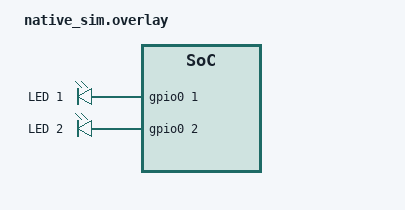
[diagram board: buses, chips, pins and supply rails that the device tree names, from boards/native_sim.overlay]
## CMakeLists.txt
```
# SPDX-License-Identifier: Apache-2.0

cmake_minimum_required(VERSION 3.28.0)

find_package(Zephyr REQUIRED HINTS $ENV{ZEPHYR_BASE})
project(projeto)

target_sources(app PRIVATE src/main.c src/led_ctrl.c)
```

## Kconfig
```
# SPDX-License-Identifier: Apache-2.0

menu "Modulo de LED (led_ctrl)"

config APP_LED_PERIOD_SLOW_MS
	int "Periodo do padrao lento (ms, ciclo completo aceso+apagado)"
	default 2000
	range 2 60000

config APP_LED_PERIOD_NORMAL_MS
	int "Periodo do padrao normal (ms, ciclo completo aceso+apagado)"
	default 1000
	range 2 60000

config APP_LED_PERIOD_FAST_MS
	int "Periodo do padrao rapido (ms, ciclo completo aceso+apagado)"
	default 250
	range 2 60000

config APP_LED_MAX_ALIASES
	int "Quantos aliases ledN do devicetree procurar (led0 .. ledN-1)"
	default 8
	range 1 64
	help
	  O modulo usa todo alias led0, led1, ... que existir abaixo deste
	  limite. LED novo exige apenas um alias novo no devicetree.

endmenu

source "Kconfig.zephyr"
```

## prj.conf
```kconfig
# nothing here
CONFIG_GPIO=y
CONFIG_GPIO_EMUL=y
```

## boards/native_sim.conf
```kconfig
# Liga a UART0 ao stdin/stdout do terminal, para ler o espaço digitado.
CONFIG_SERIAL=y
CONFIG_UART_NATIVE_PTY_0_ON_STDINOUT=y
```

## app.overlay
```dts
#include <zephyr/dt-bindings/input/input-event-codes.h>

/ {
        aliases {
                sw0 = &button0;
        };
        buttons {
                compatible = "gpio-keys";
                btn: button0 {
                        label = "SW0";
                        gpios = <&gpio0 1 GPIO_ACTIVE_HIGH>;
                };
        }
        
}
```

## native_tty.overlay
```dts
/*
 * Troca a uart1 do native_sim para o driver native_tty, que conversa
 * com um TTY real do host. Crie o par de terminais antes de rodar:
 *   socat -d -d pty,raw,echo=0,link=/tmp/ttyV0 pty,raw,echo=0,link=/tmp/ttyV1
 * Build:
 *   west build -p -b native_sim -- -DEXTRA_DTC_OVERLAY_FILE=native_tty.overlay
 */

&uart1 {
	compatible = "zephyr,native-tty-uart";
	current-speed = <115200>;
	serial-port = "/tmp/ttyV0";
	status = "okay";
};
```

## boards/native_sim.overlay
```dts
/* O native_sim já define led0 (gpio0 pino 0); acrescenta led1 e led2. */
/ {
	aliases {
		led1 = &led1;
		led2 = &led2;
	};
};

&leds {
	led1: led_1 {
		gpios = <&gpio0 1 GPIO_ACTIVE_HIGH>;
		label = "LED 1";
	};

	led2: led_2 {
		gpios = <&gpio0 2 GPIO_ACTIVE_HIGH>;
		label = "LED 2";
	};
};
```

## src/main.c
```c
/*******************************************************************
 * @file main.c
 *
 * @brief Main file.
 * @author João Matheus Nascimento Dias (jmnd@ic.ufal.br)
 * @version 0.1
 * @date 19/10/2026
 *******************************************************************/
#include "led_ctrl.h"

#include <zephyr/kernel.h>
#include <zephyr/logging/log.h>

LOG_MODULE_REGISTER(main, LOG_LEVEL_DBG);

/* Padrão de cada LED na demonstração (LED i usa o padrão i % LED_PATTERN_COUNT). */
static const enum led_pattern demo_pattern[LED_PATTERN_COUNT] = {
	LED_PATTERN_SLOW,
	LED_PATTERN_FAST,
	LED_PATTERN_NORMAL,
};

int main(void)
{
	int ret;

	LOG_INF("Atividade 05: LEDs independentes com um k_timer (%s)", CONFIG_BOARD);

	ret = led_ctrl_init();
	if (ret != 0) {
		LOG_ERR("led_ctrl_init falhou: %d", ret);
		return ret;
	}

	for (size_t i = 0; i < led_ctrl_count(); i++) {
		enum led_pattern pattern = demo_pattern[i % LED_PATTERN_COUNT];

		ret = led_ctrl_blink((int)i, pattern);
		if (ret != 0) {
			LOG_ERR("led_ctrl_blink(%zu) falhou: %d", i, ret);
			return ret;
		}
		LOG_INF("LED %zu piscando no padrao %d", i, (int)pattern);
	}

	/* O pisca segue pelo timer; main pode terminar. */
	return 0;
}
```

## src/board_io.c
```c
/*******************************************************************
 * @file board_io.c
 *
 * @brief LED e botão obtidos pelo devicetree (aliases led0 e sw0).
 *******************************************************************/

#include "board_io.h"

#include <zephyr/drivers/gpio.h>
#include <zephyr/kernel.h>

static const struct gpio_dt_spec led = GPIO_DT_SPEC_GET(DT_ALIAS(led0), gpios);
static const struct gpio_dt_spec button = GPIO_DT_SPEC_GET(DT_ALIAS(sw0), gpios);

/* Ler de volta um pino de saída não é portátil: guarda o estado aqui. */
static bool led_state;

int board_io_init(void)
{
	int ret;

	if (!gpio_is_ready_dt(&led) || !gpio_is_ready_dt(&button)) {
		return -ENODEV;
	}

	ret = gpio_pin_configure_dt(&led, GPIO_OUTPUT_INACTIVE);
	if (ret != 0) {
		return ret;
	}

	return gpio_pin_configure_dt(&button, GPIO_INPUT);
}

static int led_set(bool on)
{
	int ret = gpio_pin_set_dt(&led, on ? 1 : 0);

	if (ret == 0) {
		led_state = on;
	}
	return ret;
}

static bool led_get(void)
{
	return led_state;
}

static int button_get(void)
{
	return gpio_pin_get_dt(&button);
}

static int64_t uptime_ms(void)
{
	return k_uptime_get();
}

const struct command_hal board_hal = {
	.led_set = led_set,
	.led_get = led_get,
	.button_get = button_get,
	.uptime_ms = uptime_ms,
};
```

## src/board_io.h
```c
/*******************************************************************
 * @file board_io.h
 *
 * @brief LED e botão obtidos pelo devicetree (aliases led0 e sw0).
 *******************************************************************/

#pragma once

#include "command.h"

/* Configura led0 (saída, apagado) e sw0 (entrada). */
int board_io_init(void);

/* Implementação real das operações usadas pelos comandos. */
extern const struct command_hal board_hal;
```

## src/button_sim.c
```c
/*******************************************************************
 * @file button_sim.c
 *
 * @brief Simula o botão sw0 no native_sim: cada espaço digitado no
 *        terminal (via UART0 em stdin) gera um aperto no pino emulado.
 *******************************************************************/

#include <zephyr/device.h>
#include <zephyr/drivers/gpio.h>
#include <zephyr/drivers/gpio/gpio_emul.h>
#include <zephyr/drivers/uart.h>
#include <zephyr/kernel.h>

#define PRESS_TIME_MS 50
#define POLL_TIME_MS  10

static const struct device *const uart = DEVICE_DT_GET(DT_NODELABEL(uart0));
static const struct gpio_dt_spec button = GPIO_DT_SPEC_GET(DT_ALIAS(sw0), gpios);

static void button_sim_thread(void)
{
	unsigned char c;

	while (true) {
		if (uart_poll_in(uart, &c) == 0 && c == ' ') {
			/* Nível físico: ativo = 1 (GPIO_ACTIVE_HIGH no overlay). */
			gpio_emul_input_set(button.port, button.pin, 1);
			k_msleep(PRESS_TIME_MS);
			gpio_emul_input_set(button.port, button.pin, 0);
		}
		k_msleep(POLL_TIME_MS);
	}
}

K_THREAD_DEFINE(button_sim, 1024, button_sim_thread, NULL, NULL, NULL,
		K_LOWEST_APPLICATION_THREAD_PRIO, 0, 0);
```

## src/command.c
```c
/*******************************************************************
 * @file command.c
 *
 * @brief Implementação do parser/dispatcher de comandos (Atividade-04).
 *
 * Baseado na tabela de function pointers da Atividade-02, agora
 * indexada pelo nome do comando em vez de um enum.
 *******************************************************************/

#include "command.h"

#include <ctype.h>
#include <stdarg.h>
#include <stdio.h>
#include <string.h>
#include <strings.h>

struct command {
	const char *name;
	const char *help;
	command_handler_t handler;
};

static int handle_help(const struct command_hal *hal, const char *arg, struct cmd_out *out);
static int handle_led(const struct command_hal *hal, const char *arg, struct cmd_out *out);
static int handle_btn(const struct command_hal *hal, const char *arg, struct cmd_out *out);
static int handle_uptime(const struct command_hal *hal, const char *arg, struct cmd_out *out);
static int handle_echo(const struct command_hal *hal, const char *arg, struct cmd_out *out);

static const struct command command_table[] = {
	{"HELP", "HELP: lista os comandos", handle_help},
	{"LED", "LED [ON|OFF]: liga/desliga o led0 ou mostra seu estado", handle_led},
	{"BTN", "BTN: le o botao sw0", handle_btn},
	{"UPTIME", "UPTIME: tempo desde o boot em ms", handle_uptime},
	{"ECHO", "ECHO <texto>: devolve o texto", handle_echo},
};

#define COMMAND_TABLE_SIZE (sizeof(command_table) / sizeof(command_table[0]))

/* Acrescenta texto formatado ao buffer, truncando sem estourar. */
static void out_printf(struct cmd_out *out, const char *fmt, ...)
{
	va_list args;
	int n;

	if (out->len >= out->size) {
		return;
	}

	va_start(args, fmt);
	n = vsnprintf(out->buf + out->len, out->size - out->len, fmt, args);
	va_end(args);

	if (n < 0) {
		return;
	}

	out->len += (size_t)n;
	if (out->len >= out->size) {
		out->len = out->size - 1;
	}
}

static bool arg_is_empty(const char *arg)
{
	while (isspace((unsigned char)*arg)) {
		arg++;
	}
	return *arg == '\0';
}

int parse_command(const char *cmd)
{
	if (cmd == NULL) {
		return -1;
	}
	if (strcasecmp(cmd, "ON") == 0) {
		return 1;
	}
	if (strcasecmp(cmd, "OFF") == 0) {
		return 0;
	}
	return -1;
}

static int handle_help(const struct command_hal *hal, const char *arg, struct cmd_out *out)
{
	(void)hal;

	if (!arg_is_empty(arg)) {
		return -ENOCMD;
	}

	for (size_t i = 0; i < COMMAND_TABLE_SIZE; i++) {
		out_printf(out, "%s\r\n", command_table[i].help);
	}
	return 0;
}

static int handle_led(const struct command_hal *hal, const char *arg, struct cmd_out *out)
{
	char word[8];
	size_t len;
	int on;

	if (arg_is_empty(arg)) {
		out_printf(out, "LED: %s\r\n", hal->led_get() ? "ON" : "OFF");
		return 0;
	}

	/* Isola o argumento sem espaços nas pontas para o parse_command. */
	while (isspace((unsigned char)*arg)) {
		arg++;
	}
	len = strlen(arg);
	while (len > 0 && isspace((unsigned char)arg[len - 1])) {
		len--;
	}
	if (len >= sizeof(word)) {
		return -ENOCMD;
	}
	memcpy(word, arg, len);
	word[len] = '\0';

	on = parse_command(word);
	if (on < 0) {
		return -ENOCMD;
	}

	if (hal->led_set(on == 1) != 0) {
		out_printf(out, "ERR: led failure\r\n");
		return 0;
	}
	out_printf(out, "OK\r\n");
	return 0;
}

static int handle_btn(const struct command_hal *hal, const char *arg, struct cmd_out *out)
{
	int value;

	if (!arg_is_empty(arg)) {
		return -ENOCMD;
	}

	value = hal->button_get();
	if (value < 0) {
		out_printf(out, "ERR: button failure\r\n");
		return 0;
	}
	out_printf(out, "BTN: %d\r\n", value ? 1 : 0);
	return 0;
}

static int handle_uptime(const struct command_hal *hal, const char *arg, struct cmd_out *out)
{
	if (!arg_is_empty(arg)) {
		return -ENOCMD;
	}

	out_printf(out, "UPTIME: %lld ms\r\n", (long long)hal->uptime_ms());
	return 0;
}

static int handle_echo(const struct command_hal *hal, const char *arg, struct cmd_out *out)
{
	(void)hal;

	out_printf(out, "%s\r\n", arg);
	return 0;
}

uint16_t dispatch(const struct command_hal *hal, const char *line, char *out, size_t out_size)
{
	struct cmd_out o = {.buf = out, .size = out_size, .len = 0};
	const char *arg;
	size_t name_len;

	if (out_size == 0) {
		return ENOCMD;
	}
	out[0] = '\0';

	while (*line == ' ') {
		line++;
	}
	if (*line == '\0') {
		return 0;
	}

	/* Nome = primeira palavra; argumento = tudo após o primeiro espaço. */
	arg = strchr(line, ' ');
	if (arg != NULL) {
		name_len = (size_t)(arg - line);
		arg++;
	} else {
		name_len = strlen(line);
		arg = "";
	}

	for (size_t i = 0; i < COMMAND_TABLE_SIZE; i++) {
		const struct command *cmd = &command_table[i];

		if (strlen(cmd->name) == name_len && strncasecmp(cmd->name, line, name_len) == 0) {
			if (cmd->handler(hal, arg, &o) == 0) {
				return 0;
			}
			break;
		}
	}

	o.len = 0;
	out[0] = '\0';
	out_printf(&o, "ERR: unknown command\r\n");
	return ENOCMD;
}
```

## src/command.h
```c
/*******************************************************************
 * @file command.h
 *
 * @brief Parser e dispatcher de comandos em texto (Atividade-04).
 *
 * Camada pura: não chama UART, GPIO nem printk. Recebe uma linha,
 * consulta a tabela de comandos (function pointers) e escreve a
 * resposta num buffer. O acesso ao hardware é injetado via
 * struct command_hal, o que permite testar com fakes.
 *******************************************************************/

#pragma once

#include <stdbool.h>
#include <stddef.h>
#include <stdint.h>

#define ENOCMD 1 /* Codigo de erro comando não existe */

/* Operações de hardware usadas pelos comandos. */
struct command_hal {
	int (*led_set)(bool on);
	bool (*led_get)(void);
	int (*button_get)(void);
	int64_t (*uptime_ms)(void);
};

/* Cursor de escrita no buffer de resposta. */
struct cmd_out {
	char *buf;
	size_t size;
	size_t len;
};

/* Retorna 0 em sucesso ou -ENOCMD se o argumento não for aceito. */
typedef int (*command_handler_t)(const struct command_hal *hal, const char *arg,
				 struct cmd_out *out);

/* "ON" -> 1, "OFF" -> 0 (sem diferenciar maiúsculas), qualquer outro -> -1. */
int parse_command(const char *cmd);

/*
 * Executa a linha e escreve a resposta em out (cada linha terminada em
 * "\r\n", string sempre terminada em NUL). Linha vazia gera resposta vazia.
 * Retorna 0 ou ENOCMD (resposta "ERR: unknown command").
 */
uint16_t dispatch(const struct command_hal *hal, const char *line, char *out, size_t out_size);
```

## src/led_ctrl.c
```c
/*******************************************************************
 * @file led_ctrl.c
 *
 * @brief LEDs independentes multiplexados em um único k_timer.
 *
 * Cada LED guarda o seu próximo instante de troca (deadline absoluto,
 * em ticks). O timer é one-shot e sempre rearmado para o menor deadline;
 * como os deadlines são absolutos, rearmar por causa de um LED não muda
 * a fase nem o período dos outros. LED parado tem deadline LED_NEVER,
 * então callback e reagendamento só comparam deadlines.
 *******************************************************************/

#include "led_ctrl.h"

#include <errno.h>
#include <stdint.h>

#include <zephyr/drivers/gpio.h>
#include <zephyr/kernel.h>
#include <zephyr/logging/log.h>
#include <zephyr/spinlock.h>
#include <zephyr/sys/util.h>

LOG_MODULE_REGISTER(led_ctrl, LOG_LEVEL_INF);

#define LED_NEVER INT64_MAX

/* Uma entrada por alias ledN existente no devicetree. */
#define LED_SPEC(i, _)                                                                             \
	IF_ENABLED(DT_HAS_ALIAS(led##i), (GPIO_DT_SPEC_GET(DT_ALIAS(led##i), gpios), ))

static const struct gpio_dt_spec led_specs[] = {LISTIFY(CONFIG_APP_LED_MAX_ALIASES, LED_SPEC, ())};

#define LED_COUNT ARRAY_SIZE(led_specs)

BUILD_ASSERT(LED_COUNT > 0, "defina ao menos o alias led0 no devicetree");

/* Período (ciclo completo, ms) de cada padrão, indexado por enum led_pattern. */
static const uint32_t pattern_period_ms[LED_PATTERN_COUNT] = {
	[LED_PATTERN_SLOW] = CONFIG_APP_LED_PERIOD_SLOW_MS,
	[LED_PATTERN_NORMAL] = CONFIG_APP_LED_PERIOD_NORMAL_MS,
	[LED_PATTERN_FAST] = CONFIG_APP_LED_PERIOD_FAST_MS,
};

struct led_state {
	enum led_pattern pattern;
	k_ticks_t half_period; /* intervalo entre trocas de nível */
	k_ticks_t deadline;    /* próxima troca (uptime em ticks) ou LED_NEVER */
	bool blinking;
};

static struct led_state leds[LED_COUNT];
static struct k_timer led_timer;
static bool timer_initialized;
static struct k_spinlock lock;

/* Ação aplicada a um LED com o lock tomado. */
typedef int (*led_action_fn)(size_t idx, enum led_pattern pattern);

/* Arma o timer para o deadline mais próximo. Chamar com o lock tomado. */
static void reschedule(void)
{
	k_ticks_t next = LED_NEVER;

	for (size_t i = 0; i < LED_COUNT; i++) {
		next = MIN(next, leds[i].deadline);
	}

	if (next == LED_NEVER) {
		k_timer_stop(&led_timer);
		return;
	}
	k_timer_start(&led_timer, K_TIMEOUT_ABS_TICKS(next), K_NO_WAIT);
}

/* Contexto de ISR: só GPIO, deadlines e rearme. */
static void led_timer_expiry(struct k_timer *timer)
{
	k_spinlock_key_t key = k_spin_lock(&lock);
	k_ticks_t now = k_uptime_ticks();

	ARG_UNUSED(timer);

	for (size_t i = 0; i < LED_COUNT; i++) {
		if (leds[i].deadline <= now) {
			(void)gpio_pin_toggle_dt(&led_specs[i]);
			leds[i].deadline += leds[i].half_period;
		}
	}
	reschedule();

	k_spin_unlock(&lock, key);
}

static void stop_blink(size_t idx)
{
	leds[idx].blinking = false;
	leds[idx].deadline = LED_NEVER;
}

static int action_on(size_t idx, enum led_pattern pattern)
{
	ARG_UNUSED(pattern);
	stop_blink(idx);
	return gpio_pin_set_dt(&led_specs[idx], 1);
}

static int action_off(size_t idx, enum led_pattern pattern)
{
	ARG_UNUSED(pattern);
	stop_blink(idx);
	return gpio_pin_set_dt(&led_specs[idx], 0);
}

static int action_toggle(size_t idx, enum led_pattern pattern)
{
	ARG_UNUSED(pattern);
	stop_blink(idx);
	return gpio_pin_toggle_dt(&led_specs[idx]);
}

static int action_blink(size_t idx, enum led_pattern pattern)
{
	struct led_state *led = &leds[idx];
	int ret = gpio_pin_set_dt(&led_specs[idx], 1);

	if (ret != 0) {
		stop_blink(idx);
		return ret;
	}

	led->pattern = pattern;
	led->half_period = k_ms_to_ticks_ceil64(pattern_period_ms[pattern] / 2U);
	led->deadline = k_uptime_ticks() + led->half_period;
	led->blinking = true;
	return 0;
}

/* Único lugar que trata "um LED ou todos": resolve o intervalo e aplica a ação. */
static int led_apply(int led, led_action_fn action, enum led_pattern pattern)
{
	size_t first = 0;
	size_t last = LED_COUNT;
	k_spinlock_key_t key;
	int ret = 0;

	if (led != LED_CTRL_ALL) {
		if (led < 0 || (size_t)led >= LED_COUNT) {
			LOG_ERR("LED invalido: %d (existem %zu)", led, LED_COUNT);
			return -EINVAL;
		}
		first = (size_t)led;
		last = first + 1;
	}

	if (!timer_initialized) {
		LOG_ERR("led_ctrl_init() ainda nao foi chamada");
		return -EPERM;
	}

	key = k_spin_lock(&lock);
	for (size_t i = first; i < last && ret == 0; i++) {
		ret = action(i, pattern);
	}
	reschedule();
	k_spin_unlock(&lock, key);

	return ret;
}

int led_ctrl_init(void)
{
	k_spinlock_key_t key;

	for (size_t i = 0; i < LED_COUNT; i++) {
		if (!gpio_is_ready_dt(&led_specs[i])) {
			LOG_ERR("controlador do LED %zu (%s) nao esta pronto", i,
				led_specs[i].port->name);
			return -ENODEV;
		}
	}

	/* k_timer_init num timer ativo corromperia a fila de timeouts: só na 1a vez. */
	if (!timer_initialized) {
		k_timer_init(&led_timer, led_timer_expiry, NULL);
		timer_initialized = true;
	}

	key = k_spin_lock(&lock);
	k_timer_stop(&led_timer);
	for (size_t i = 0; i < LED_COUNT; i++) {
		stop_blink(i);
	}
	k_spin_unlock(&lock, key);

	for (size_t i = 0; i < LED_COUNT; i++) {
		int ret = gpio_pin_configure_dt(&led_specs[i], GPIO_OUTPUT_INACTIVE);

		if (ret != 0) {
			LOG_ERR("falha ao configurar LED %zu: %d", i, ret);
			return ret;
		}
	}

	return 0;
}

size_t led_ctrl_count(void)
{
	return LED_COUNT;
}

int led_ctrl_on(int led)
{
	return led_apply(led, action_on, LED_PATTERN_SLOW);
}

int led_ctrl_off(int led)
{
	return led_apply(led, action_off, LED_PATTERN_SLOW);
}

int led_ctrl_toggle(int led)
{
	return led_apply(led, action_toggle, LED_PATTERN_SLOW);
}

int led_ctrl_blink(int led, enum led_pattern pattern)
{
	if ((unsigned int)pattern >= LED_PATTERN_COUNT) {
		LOG_ERR("padrao invalido: %d", (int)pattern);
		return -EINVAL;
	}
	return led_apply(led, action_blink, pattern);
}
```

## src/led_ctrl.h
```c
/*******************************************************************
 * @file led_ctrl.h
 *
 * @brief Driver de LEDs independentes multiplexados em um único k_timer.
 *
 * O resto do código pede "LED 1 piscando devagar" e não sabe nada de
 * timer. Os LEDs vêm do devicetree (aliases led0, led1, ...); o índice
 * de cada LED é a sua posição nessa lista.
 *
 * Toda função de ação aceita LED_CTRL_ALL para agir em todos os LEDs.
 * LED ou padrão fora do intervalo retorna -EINVAL.
 *******************************************************************/

#pragma once

#include <stddef.h>

/* Índice especial: aplica a ação a todos os LEDs. */
#define LED_CTRL_ALL (-1)

/* Padrões de pisca; períodos definidos por Kconfig (APP_LED_PERIOD_*). */
enum led_pattern {
	LED_PATTERN_SLOW,
	LED_PATTERN_NORMAL,
	LED_PATTERN_FAST,
	LED_PATTERN_COUNT,
};

/*
 * Verifica os controladores GPIO e configura todos os LEDs como saída,
 * desligados, cancelando qualquer pisca. Pode ser chamada de novo.
 * Retorna 0, -ENODEV se algum controlador não estiver pronto, ou o erro
 * da configuração do GPIO.
 */
int led_ctrl_init(void);

/* Quantidade de LEDs encontrados no devicetree. */
size_t led_ctrl_count(void);

/* Ligar, desligar e alternar cancelam o pisca em andamento do LED. */
int led_ctrl_on(int led);
int led_ctrl_off(int led);
int led_ctrl_toggle(int led);

/* Começa a piscar o LED (aceso primeiro) no padrão escolhido. */
int led_ctrl_blink(int led, enum led_pattern pattern);
```

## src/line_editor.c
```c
/*******************************************************************
 * @file line_editor.c
 *
 * @brief Montagem de linhas com backspace e descarte de linha longa.
 *******************************************************************/

#include "line_editor.h"

#define KEY_BACKSPACE 0x08
#define KEY_DELETE    0x7F

void line_editor_init(struct line_editor *le, char *buf, size_t size)
{
	le->buf = buf;
	le->size = size;
	le->len = 0;
	le->overflow = false;
	le->last_cr = false;
	if (size > 0) {
		buf[0] = '\0';
	}
}

static enum line_event finish_line(struct line_editor *le)
{
	bool overflow = le->overflow;

	le->buf[le->len] = '\0';
	le->len = 0;
	le->overflow = false;

	return overflow ? LINE_TOO_LONG : LINE_DONE;
}

enum line_event line_editor_feed(struct line_editor *le, char c)
{
	bool after_cr = le->last_cr;

	le->last_cr = (c == '\r');

	if (c == '\r' || c == '\n') {
		/* "\r\n" conta como um único terminador. */
		if (c == '\n' && after_cr) {
			return LINE_IGNORED;
		}
		return finish_line(le);
	}

	if (c == KEY_BACKSPACE || c == KEY_DELETE) {
		/* Linha já condenada: nada a apagar até o terminador. */
		if (le->overflow || le->len == 0) {
			return LINE_IGNORED;
		}
		le->len--;
		return LINE_ERASED;
	}

	if ((unsigned char)c < 0x20) {
		return LINE_IGNORED;
	}

	/* Sem espaço (inclusive após o overflow): descarta até o terminador. */
	if (le->len + 1 >= le->size) {
		le->overflow = true;
		return LINE_CHAR;
	}

	le->buf[le->len++] = c;
	return LINE_CHAR;
}
```

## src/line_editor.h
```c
/*******************************************************************
 * @file line_editor.h
 *
 * @brief Montagem de linhas a partir de bytes recebidos (Atividade-04).
 *
 * Camada pura: não faz I/O. Cada byte alimentado retorna um evento
 * que diz ao transporte o que ecoar ou se a linha está pronta.
 *******************************************************************/

#pragma once

#include <stdbool.h>
#include <stddef.h>

enum line_event {
	LINE_IGNORED,  /* nada a fazer */
	LINE_CHAR,     /* caractere aceito: ecoar o byte */
	LINE_ERASED,   /* último caractere apagado: ecoar "\b \b" */
	LINE_DONE,     /* linha completa em buf (terminada em NUL) */
	LINE_TOO_LONG, /* linha excedeu o buffer e foi descartada */
};

struct line_editor {
	char *buf;
	size_t size; /* inclui o NUL: aceita até size - 1 caracteres */
	size_t len;
	bool overflow;
	bool last_cr;
};

void line_editor_init(struct line_editor *le, char *buf, size_t size);

/*
 * Processa um byte. Após LINE_DONE a linha fica em le->buf até o
 * próximo byte alimentado, que começa uma linha nova.
 */
enum line_event line_editor_feed(struct line_editor *le, char c);
```

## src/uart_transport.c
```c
/*******************************************************************
 * @file uart_transport.c
 *
 * @brief Transporte da mini-shell por UART.
 *
 * ISR: só copia os bytes recebidos para uma fila.
 * Thread: consome a fila, ecoa, monta linhas e despacha comandos.
 * TX: uart_poll_out.
 *******************************************************************/

#include "uart_transport.h"

#include <zephyr/drivers/uart.h>
#include <zephyr/kernel.h>

#include "line_editor.h"

#define RX_QUEUE_LEN      128
#define RESPONSE_SIZE     256
#define SHELL_STACK_SIZE  2048
#define SHELL_THREAD_PRIO 5

K_MSGQ_DEFINE(rx_queue, sizeof(uint8_t), RX_QUEUE_LEN, 1);
K_THREAD_STACK_DEFINE(shell_stack, SHELL_STACK_SIZE);

static struct k_thread shell_thread;
static const struct device *shell_uart;
static const struct command_hal *shell_hal;

static void uart_isr(const struct device *dev, void *user_data)
{
	uint8_t buf[16];
	int n;

	ARG_UNUSED(user_data);

	uart_irq_update(dev);

	while (uart_irq_rx_ready(dev) > 0) {
		n = uart_fifo_read(dev, buf, sizeof(buf));
		if (n <= 0) {
			break;
		}
		for (int i = 0; i < n; i++) {
			/* Fila cheia: o byte é perdido (não bloqueia na ISR). */
			(void)k_msgq_put(&rx_queue, &buf[i], K_NO_WAIT);
		}
	}
}

static void send_str(const char *s)
{
	while (*s != '\0') {
		uart_poll_out(shell_uart, *s++);
	}
}

static void shell_thread_fn(void *p1, void *p2, void *p3)
{
	static char line[CONFIG_APP_CMD_LINE_SIZE];
	static char response[RESPONSE_SIZE];
	struct line_editor le;
	uint8_t c;

	ARG_UNUSED(p1);
	ARG_UNUSED(p2);
	ARG_UNUSED(p3);

	line_editor_init(&le, line, sizeof(line));
	send_str("> ");

	while (true) {
		k_msgq_get(&rx_queue, &c, K_FOREVER);

		switch (line_editor_feed(&le, (char)c)) {
		case LINE_CHAR:
			uart_poll_out(shell_uart, c);
			break;
		case LINE_ERASED:
			send_str("\b \b");
			break;
		case LINE_DONE:
			send_str("\r\n");
			dispatch(shell_hal, line, response, sizeof(response));
			send_str(response);
			send_str("> ");
			break;
		case LINE_TOO_LONG:
			send_str("\r\nERR: line too long\r\n> ");
			break;
		case LINE_IGNORED:
		default:
			break;
		}
	}
}

int uart_transport_start(const struct device *uart, const struct command_hal *hal)
{
	int ret;

	shell_uart = uart;
	shell_hal = hal;

	ret = uart_irq_callback_user_data_set(uart, uart_isr, NULL);
	if (ret != 0) {
		return ret;
	}

	k_thread_create(&shell_thread, shell_stack, K_THREAD_STACK_SIZEOF(shell_stack),
			shell_thread_fn, NULL, NULL, NULL, SHELL_THREAD_PRIO, 0, K_NO_WAIT);
	k_thread_name_set(&shell_thread, "shell");

	uart_irq_rx_enable(uart);
	return 0;
}
```

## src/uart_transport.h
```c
/*******************************************************************
 * @file uart_transport.h
 *
 * @brief Transporte da mini-shell por UART (RX por interrupção).
 *******************************************************************/

#pragma once

#include <zephyr/device.h>

#include "command.h"

/*
 * Liga a interrupção de RX da UART e inicia a thread que monta as
 * linhas e despacha os comandos. Retorna 0 ou erro negativo.
 */
int uart_transport_start(const struct device *uart, const struct command_hal *hal);
```
